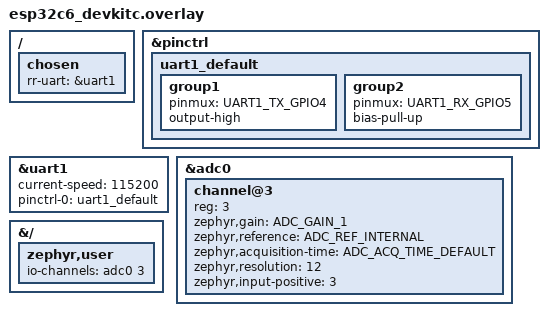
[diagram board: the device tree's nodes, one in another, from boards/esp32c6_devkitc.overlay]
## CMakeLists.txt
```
cmake_minimum_required(VERSION 3.20.0)
find_package(Zephyr REQUIRED HINTS $ENV{ZEPHYR_BASE})
project(tuner_pulley_embed)

# target_sources(app PRIVATE src/main.c)
target_sources(app PRIVATE src/main.c wasmtime-rr-prototyping/adc_embed_nostd/src/bridge.c)

# ---- Rust integration ----
set(RUST_CRATE_DIR ${CMAKE_CURRENT_SOURCE_DIR}/wasmtime-rr-prototyping/adc_embed_nostd)
set(RUST_TARGET riscv32imac-unknown-none-elf)
set(RUST_PROFILE release)

# Update this if your crate name differs:
set(RUST_LIB ${CMAKE_CURRENT_SOURCE_DIR}/wasmtime-rr-prototyping/target/${RUST_TARGET}/${RUST_PROFILE}/libadc_embed_nostd.a)


target_link_libraries(app PUBLIC "${RUST_LIB}")

# 2. The Custom Command to actually run Cargo
add_custom_command(
    OUTPUT "${RUST_LIB_PATH}"
    COMMAND cargo build --release --target riscv32imac-unknown-none-elf
    WORKING_DIRECTORY "${RUST_SOURCE_DIR}"
    COMMENT "Generating Rust Static Library via Cargo..."
    VERBATIM
)

# 3. Create a custom target so CMake has something to track
add_custom_target(run_cargo_build DEPENDS "${RUST_LIB_PATH}")

# 4. Create an interface library to hold the Rust archive
add_library(rust_app_lib INTERFACE)
target_link_libraries(rust_app_lib INTERFACE "${RUST_LIB_PATH}")
```

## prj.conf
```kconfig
CONFIG_PRINTK=y
CONFIG_STDOUT_CONSOLE=y
CONFIG_CONSOLE=y
CONFIG_ADC=y
CONFIG_SERIAL=y
CONFIG_UART_ESP32=y

CONFIG_SIZE_OPTIMIZATIONS=y
CONFIG_BUILD_OUTPUT_BIN=y



# Enable stack monitoring and the shell/log output
CONFIG_INIT_STACKS=y
CONFIG_STACK_USAGE=y
# CONFIG_THREAD_ANALYZER=y
# CONFIG_THREAD_ANALYZER_AUTO=n
# CONFIG_SYS_HEAP_RUNTIME_STATS=y
# CONFIG_THREAD_ANALYZER_AUTO_INTERVAL_MS=5000

# Increase the main stack size (Crucial for Wasmtime/Pulley)
CONFIG_MAIN_STACK_SIZE=53000
# CONFIG_MAIN_STACK_SIZE=63000
# CONFIG_MAIN_STACK_SIZE=95000
# CONFIG_ISR_STACK_SIZE=1024
CONFIG_ISR_STACK_SIZE=16384
# CONFIG_MAIN_STACK_SIZE=32768

# Since you are using Zephyr's allocator for Rust, 
# make sure the heap is also large enough to hold Wasm modules
CONFIG_HEAP_MEM_POOL_SIZE=307200
# CONFIG_HEAP_MEM_POOL_SIZE=262144
# CONFIG_HEAP_MEM_POOL_SIZE=253000
CONFIG_ADC_LOG_LEVEL_DBG=n

CONFIG_NEWLIB_LIBC=y
CONFIG_COMMON_LIBC_MALLOC_ARENA_SIZE=0

CONFIG_STACK_SENTINEL=n
CONFIG_HW_STACK_PROTECTION=n
CONFIG_BOOT_BANNER=n

#CONFIG_RUST=y

# If you need heap allocation from Rust:
#CONFIG_RUST_ALLOC=y

# CONFIG_RISCV_ISA_EXT_A=y
# CONFIG_RISCV_ISA_EXT_M=y
# CONFIG_RISCV_ISA_EXT_C=y
```

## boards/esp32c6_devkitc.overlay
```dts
/* boards/esp32c6_devkitc.overlay */
#include <zephyr/dt-bindings/pinctrl/esp-pinctrl-common.h>
#include <dt-bindings/pinctrl/esp32c6-pinctrl.h>
#include <zephyr/dt-bindings/pinctrl/esp32c6-gpio-sigmap.h>

/ {
	chosen {
		rr-uart = &uart1;
	};
};

&pinctrl {
	uart1_default: uart1_default {
		group1 {
			pinmux = <UART1_TX_GPIO4>;
			output-high;
		};
		group2 {
			pinmux = <UART1_RX_GPIO5>;
			bias-pull-up;
		};
	};
};

&uart1 {
	status = "okay";
	current-speed = <115200>;
	pinctrl-0 = <&uart1_default>;
	pinctrl-names = "default";
};

&adc0 {
	status = "okay";
	#address-cells = <1>;
	#size-cells = <0>;

	channel@3 {
		reg = <3>;
		zephyr,gain = "ADC_GAIN_1";
		zephyr,reference = "ADC_REF_INTERNAL";
		zephyr,acquisition-time = <ADC_ACQ_TIME_DEFAULT>;
		zephyr,resolution = <12>;
		zephyr,input-positive = <3>;
	};
};

&{/} {
	zephyr,user {
		io-channels = <&adc0 3>;
	};
};
```

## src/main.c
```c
#include <zephyr/kernel.h>
#include <zephyr/device.h>
#include <zephyr/devicetree.h>
#include <zephyr/drivers/i2s.h>
#include <zephyr/drivers/uart.h>
#include <stdint.h>

// Forward declaration of your Rust function
extern void rust_main(void);


int main(void) {
    // trace_uart_init();
    printk("Zephyr booting... jumping to Rust\n");

    // Call your Rust entry point
    rust_main();

    // printk("Finished Running\n");

    return 0;
}
```
